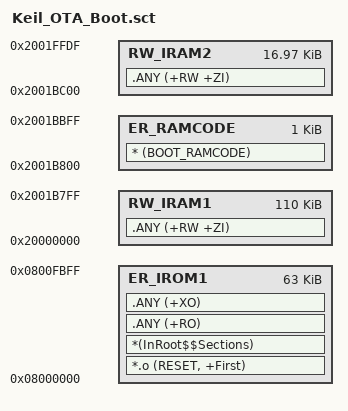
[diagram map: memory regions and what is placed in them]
; *************************************************************
; *** Bootloader 链接脚本，分区与 boot_conf.h 保持一致        ***
; *** Flash：0x08000000 起 64 KB（sector 0-3），超限即报错   ***
; *** SRAM2 顶部 32 字节 0x2001FFE0 为 Boot 邮箱，禁止分配   ***
; *** BOOT_RAMCODE：Flash 擦写函数，必须搬到 SRAM 里执行     ***
; *************************************************************

LR_IROM1 0x08000000 0x0000FC00  {    ; 代码区，留出最后 1 KB 给 RAM 函数
  ER_IROM1 0x08000000 0x0000FC00  {  ; load address = execution address
   *.o (RESET, +First)
   *(InRoot$$Sections)
   .ANY (+RO)
   .ANY (+XO)
  }
  RW_IRAM1 0x20000000 0x0001B800  {  ; RW data，上界让给 RAM 函数区
   .ANY (+RW +ZI)
  }
  RW_IRAM2 0x2001BC00 0x000043E0  {  ; 顶部 32 字节保留给 Boot 邮箱
   .ANY (+RW +ZI)
  }
}

LR_RAMCODE 0x0800FC00 0x00000400  {  ; RAM 函数在 Flash 里的初值副本
  ER_RAMCODE 0x2001B800 0x00000400  {  ; 运行时地址在 SRAM，启动时由 __main 搬运
   * (BOOT_RAMCODE)
  }
}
